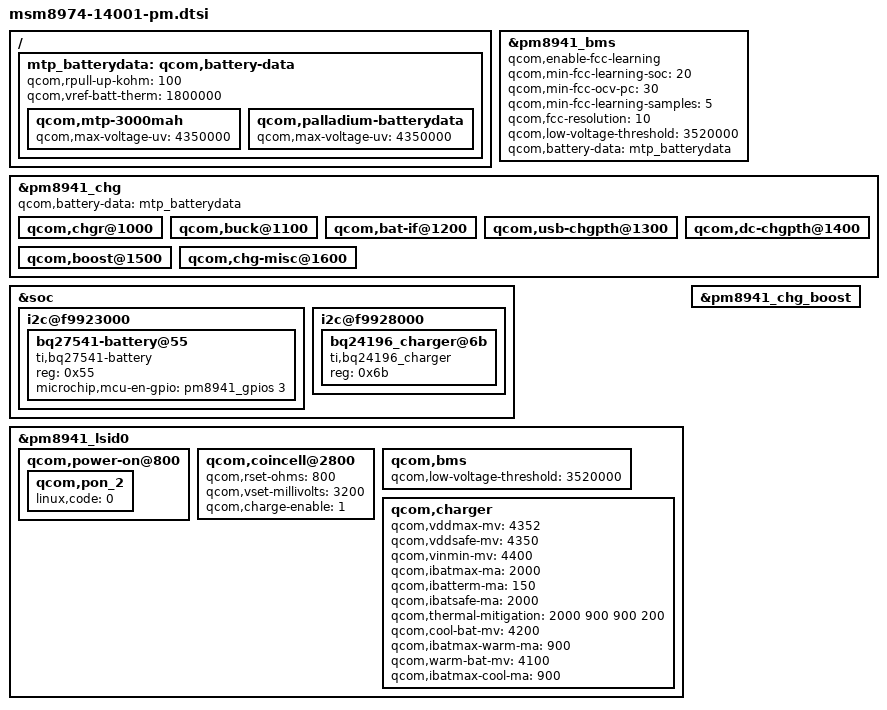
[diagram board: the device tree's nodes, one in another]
/* Copyright (c) 2012-2013, The Linux Foundation. All rights reserved.
 *
 * This program is free software; you can redistribute it and/or modify
 * it under the terms of the GNU General Public License version 2 and
 * only version 2 as published by the Free Software Foundation.
 *
 * This program is distributed in the hope that it will be useful,
 * but WITHOUT ANY WARRANTY; without even the implied warranty of
 * MERCHANTABILITY or FITNESS FOR A PARTICULAR PURPOSE.  See the
 * GNU General Public License for more details.
 */

/ {
	mtp_batterydata: qcom,battery-data {
		qcom,rpull-up-kohm = <100>;
		qcom,vref-batt-therm = <1800000>;

		/include/ "../../batterydata-palladium.dtsi"
		/include/ "../../batterydata-mtp-3000mah.dtsi"
	};
};

&pm8941_bms {
	qcom,enable-fcc-learning;
	qcom,min-fcc-learning-soc = <20>;
	qcom,min-fcc-ocv-pc = <30>;
	qcom,min-fcc-learning-samples = <5>;
	qcom,fcc-resolution = <10>;
	qcom,low-voltage-threshold = <3520000>;
	status = "ok";
	qcom,battery-data = <&mtp_batterydata>;
};

&pm8941_chg {
	status = "ok";

	qcom,battery-data = <&mtp_batterydata>;

	qcom,chgr@1000 {
		status = "ok";
	};

	qcom,buck@1100 {
		status = "ok";
	};

	qcom,bat-if@1200 {
		status = "ok";
	};

	qcom,usb-chgpth@1300 {
		status = "ok";
	};

	qcom,dc-chgpth@1400 {
		status = "ok";
	};

	qcom,boost@1500 {
		status = "ok";
	};

	qcom,chg-misc@1600 {
		status = "ok";
	};
};

&mtp_batterydata {
	qcom,mtp-3000mah {
		qcom,max-voltage-uv = <4350000>;
	};

	qcom,palladium-batterydata {
		qcom,max-voltage-uv = <4350000>;
	};
};

&soc {
	i2c@f9923000 {
		bq27541-battery@55 {
			status = "okay";
			compatible = "ti,bq27541-battery";
			reg = <0x55>;
			microchip,mcu-en-gpio = <&pm8941_gpios 3 0>;
		};
	};

	i2c@f9928000 {
		bq24196_charger@6b {
			status = "okay";
			compatible = "ti,bq24196_charger";
			reg = <0x6b>;
		};
	};
};

&pm8941_lsid0 {
	qcom,power-on@800 {
		qcom,pon_2 {
			linux,code = <0>;
		};
	};

	qcom,coincell@2800 {
		qcom,rset-ohms = <800>;
		qcom,vset-millivolts = <3200>;
		qcom,charge-enable = <1>;
	};

	qcom,bms {
		qcom,low-voltage-threshold = <3520000>;
	};

	qcom,charger {
		qcom,vddmax-mv = <4352>;
		qcom,vddsafe-mv = <4350>;
		qcom,vinmin-mv = <4400>;
		qcom,ibatmax-ma = <2000>;
		qcom,ibatterm-ma = <150>;
		qcom,ibatsafe-ma = <2000>;
		qcom,thermal-mitigation = <2000 900 900 200>;
		qcom,cool-bat-mv = <4200>;
		qcom,ibatmax-warm-ma = <900>;
		qcom,warm-bat-mv = <4100>;
		qcom,ibatmax-cool-ma = <900>;
	};
};

&pm8941_chg_boost {
	status = "ok";
};
